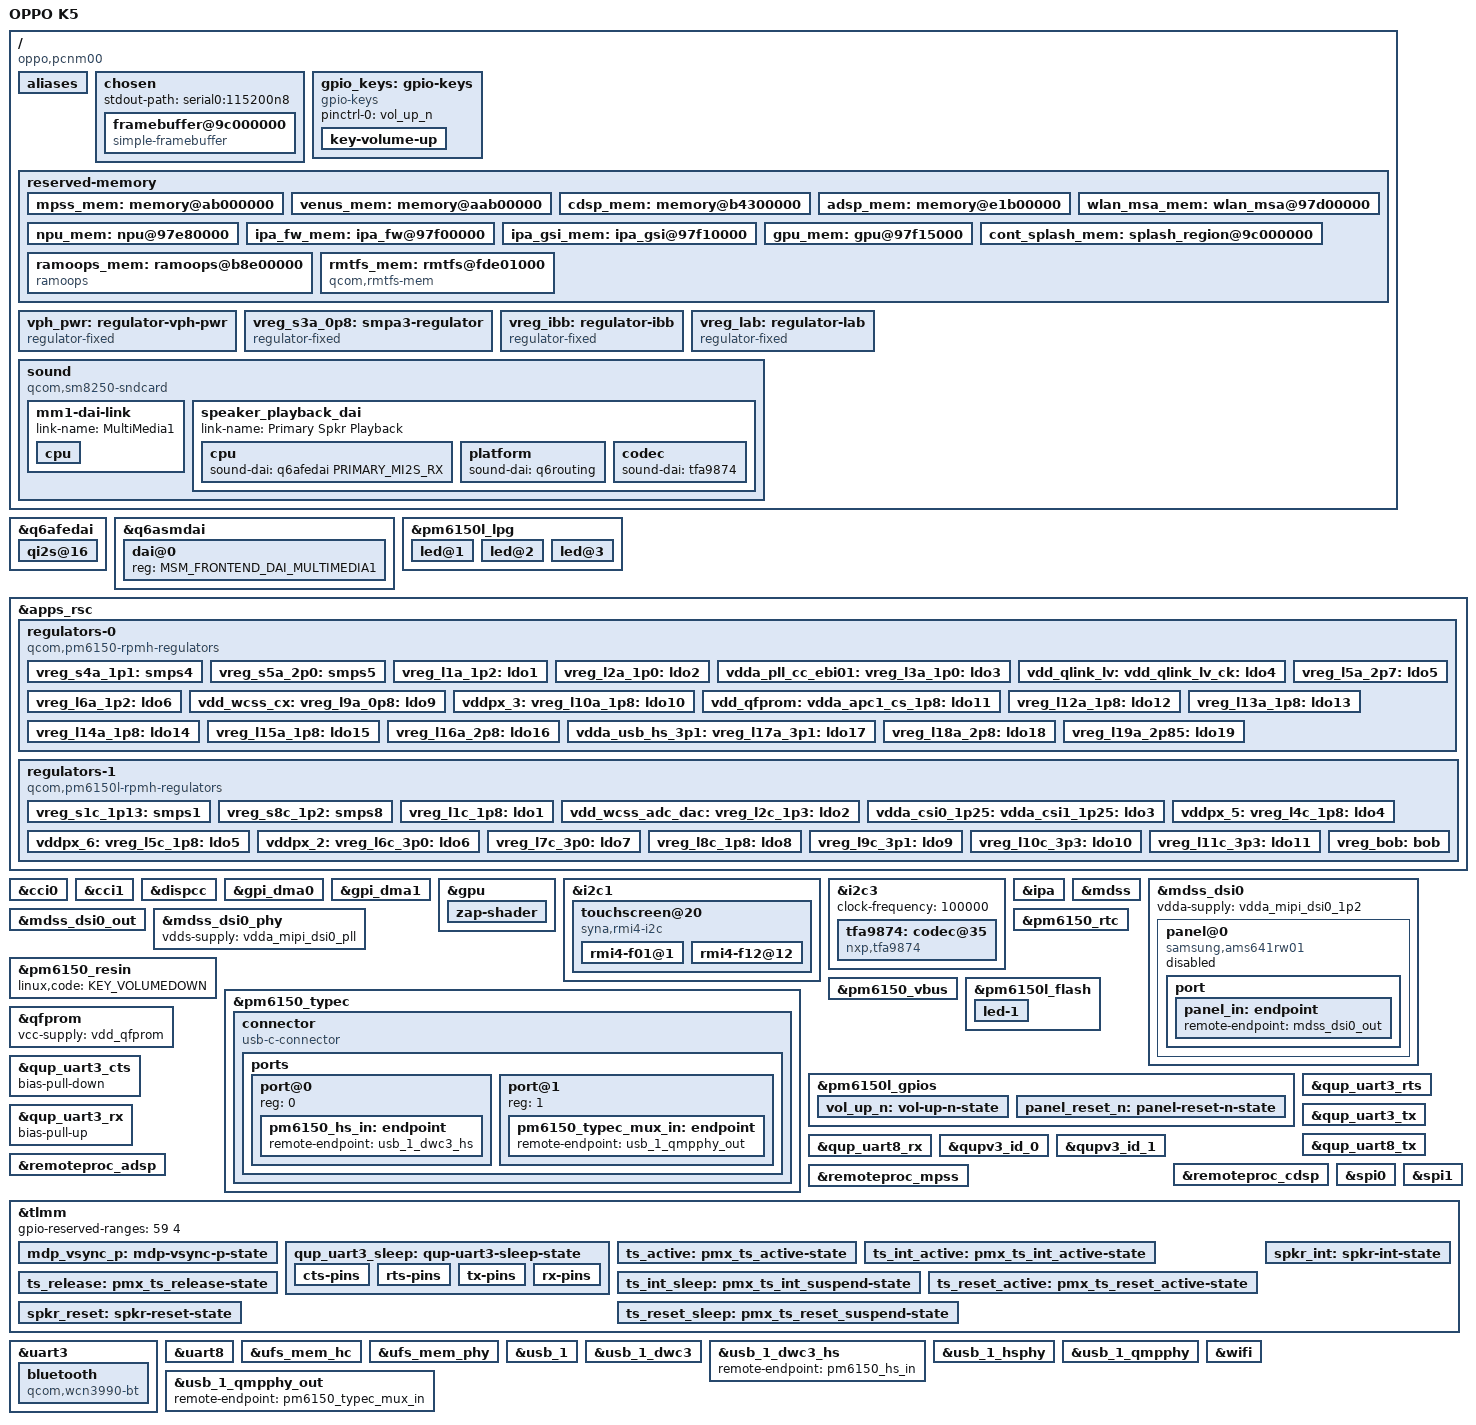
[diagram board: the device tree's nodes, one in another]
// SPDX-License-Identifier: BSD-3-Clause
/*
 * Copyright (c) 2026, XiKoTaSu <3329989998@qq.com>
 */

/dts-v1/;

#include <dt-bindings/firmware/qcom,scm.h>
#include <dt-bindings/gpio/gpio.h>
#include <dt-bindings/leds/common.h>
#include <dt-bindings/pinctrl/qcom,pmic-gpio.h>
#include <dt-bindings/regulator/qcom,rpmh-regulator.h>
#include <dt-bindings/sound/qcom,q6asm.h>
#include <dt-bindings/usb/pd.h>

#include "sm7150.dtsi"
#include "pm6150.dtsi"
#include "pm6150l.dtsi"

/delete-node/ &mpss_mem;
/delete-node/ &venus_mem;
/delete-node/ &cdsp_mem;
/delete-node/ &adsp_mem;
/delete-node/ &wlan_msa_mem;
/delete-node/ &npu_mem;
/delete-node/ &ipa_fw_mem;
/delete-node/ &ipa_gsi_mem;
/delete-node/ &gpu_mem;

/ {
	model = "OPPO K5";
	compatible = "oppo,pcnm00", "qcom,sm7150";
	chassis-type = "handset";

	aliases {
		bluetooth0 = &bluetooth;
		hsuart0 = &uart3;
		serial0 = &uart8;
		wifi0 = &wifi;
	};

	chosen {
		#address-cells = <2>;
		#size-cells = <2>;
		ranges;

		stdout-path = "serial0:115200n8";

		framebuffer@9c000000 {
			compatible = "simple-framebuffer";
			reg = <0x0 0x9c000000 0x0 0x1700000>;
			width = <1080>;
			height = <2340>;
			stride = <(1080 * 4)>;
			format = "a8r8g8b8";

			clocks = <&gcc GCC_DISP_HF_AXI_CLK>;
		};
	};

	gpio_keys: gpio-keys {
		compatible = "gpio-keys";

		pinctrl-0 = <&vol_up_n>;
		pinctrl-names = "default";

		key-volume-up {
			label = "Volume Up";
			gpios = <&pm6150l_gpios 2 GPIO_ACTIVE_LOW>;
			linux,code = <KEY_VOLUMEUP>;
			debounce-interval = <15>;
			linux,can-disable;
			wakeup-source;
		};
	};

    reserved-memory {
		mpss_mem: memory@ab000000 {
			reg = <0x0 0xab000000 0x0 0x8e00000>;
			no-map;
		};

		venus_mem: memory@aab00000 {
			reg = <0x0 0xaab00000 0x0 0x500000>;
			no-map;
		};

		cdsp_mem: memory@b4300000 {
			reg = <0x0 0xb4300000 0x0 0x1e00000>;
			no-map;
		};

		adsp_mem: memory@e1b00000 {
			reg = <0x00 0xe1b00000 0x00 0x2000000>;
			no-map;
		};

		wlan_msa_mem: wlan_msa@97d00000 {
			reg = <0x0 0x97d00000 0x0 0x180000>;
			no-map;
		};

		npu_mem: npu@97e80000 {
			reg = <0x0 0x97e80000 0x0 0x80000>;
			no-map;
		};

		ipa_fw_mem: ipa_fw@97f00000 {
			reg = <0x0 0x97f00000 0x0 0x10000>;
			no-map;
		};

		ipa_gsi_mem: ipa_gsi@97f10000 {
			reg = <0x0 0x97f10000 0x0 0x5000>;
			no-map;
		};

		gpu_mem: gpu@97f15000 {
			reg = <0x0 0x97f15000 0x0 0x2000>;
			no-map;
		};

		cont_splash_mem: splash_region@9c000000 {
			reg = <0x0 0x9c000000 0x0 0x1700000>;
			no-map;
		};

		ramoops_mem: ramoops@b8e00000 {
			compatible = "ramoops";
			reg = <0x0 0xb8e00000 0x0 0x400000>;
			record-size = <0x40000>;
			console-size = <0x40000>;
			ftrace-size = <0x40000>;
			pmsg-size = <0x200000>;
		};

		rmtfs_mem: rmtfs@fde01000 {
			compatible = "qcom,rmtfs-mem";
			reg = <0x0 0xfde01000 0x0 0x200000>;
			no-map;

			qcom,client-id = <1>;
			qcom,vmid = <QCOM_SCM_VMID_MSS_MSA>;
		};
	};

	vph_pwr: regulator-vph-pwr {
		compatible = "regulator-fixed";

		regulator-name = "vph_pwr";
		regulator-min-microvolt = <3700000>;
		regulator-max-microvolt = <3700000>;

		regulator-always-on;
		regulator-boot-on;
	};
	
	// S3A is really mx.lvl but it's there for supply map completeness sake.
	vreg_s3a_0p8: smpa3-regulator {
		compatible = "regulator-fixed";
		regulator-name = "vreg_s3a_0p8";

		regulator-min-microvolt = <800000>;
		regulator-max-microvolt = <800000>;
		regulator-always-on;
		vin-supply = <&vph_pwr>;
	};

	vreg_ibb: regulator-ibb {
		compatible = "regulator-fixed";

		regulator-name = "ibb";
		regulator-min-microvolt = <6000000>;
		regulator-max-microvolt = <6000000>;
	};

	vreg_lab: regulator-lab {
		compatible = "regulator-fixed";

		regulator-name = "lab";
		regulator-min-microvolt = <6100000>;
		regulator-max-microvolt = <6100000>;
	};

	sound {
		compatible = "qcom,sm8250-sndcard";
		pinctrl-0 = <&pri_mi2s_active &pri_mi2s_ws_active>;
		pinctrl-names = "default";
		model = "OPPO K5";

		mm1-dai-link {
			link-name = "MultiMedia1";
			cpu {
				sound-dai = <&q6asmdai MSM_FRONTEND_DAI_MULTIMEDIA1>;
			};
		};

		speaker_playback_dai {
			link-name = "Primary Spkr Playback";
			cpu {
				sound-dai = <&q6afedai PRIMARY_MI2S_RX>;
			};

			platform {
				sound-dai = <&q6routing>;
			};

			codec {
				sound-dai = <&tfa9874>;
			};
		};
	};
};

&q6afedai {
	qi2s@16 {
		reg = <PRIMARY_MI2S_RX>;
		qcom,sd-lines = <0>;
	};
};

&q6asmdai {
	dai@0 {
		reg = <MSM_FRONTEND_DAI_MULTIMEDIA1>;
	};
};

&pm6150l_lpg {
	status = "okay";

	led@1 {
		reg = <1>;
		color = <LED_COLOR_ID_RED>;
		function = LED_FUNCTION_STATUS;
		function-enumerator = <0>;
	};

	led@2 {
		reg = <2>;
		color = <LED_COLOR_ID_RED>;
		function = LED_FUNCTION_STATUS;
		function-enumerator = <1>;
	};

	led@3 {
		reg = <3>;
		color = <LED_COLOR_ID_RED>;
		function = LED_FUNCTION_STATUS;
		function-enumerator = <2>;
	};
};

&apps_rsc {
	regulators-0 {
		compatible = "qcom,pm6150-rpmh-regulators";
		qcom,pmic-id = "a";

		vdd-s1-supply = <&vph_pwr>;
		vdd-s2-supply = <&vph_pwr>;
		vdd-s3-supply = <&vph_pwr>;
		vdd-s4-supply = <&vph_pwr>;
		vdd-s5-supply = <&vph_pwr>;

		vdd-l1-supply = <&vreg_s8c_1p2>;
		vdd-l2-l3-supply = <&vreg_s4a_1p1>;
		vdd-l4-l7-l8-supply = <&vreg_s4a_1p1>;
		vdd-l5-l16-l17-l18-l19-supply = <&vreg_bob>;
		vdd-l6-supply = <&vreg_s8c_1p2>;
		vdd-l9-supply = <&vreg_s3a_0p8>;
		vdd-l10-l14-l15-supply = <&vreg_s5a_2p0>;
		vdd-l11-l12-l13-supply = <&vreg_s5a_2p0>;

		/*
		 * S1, S4, S5 are unused.
		 * S2-S3 and L7-L8 are ARCs:
		 * S2 - gfx.lvl,
		 * S3 - mx.lvl,
		 * L7 - lmx.lvl,
		 * L8 - lcx.lvl.
		 */

		vreg_s4a_1p1: smps4 {
			regulator-name = "vreg_s4a_1p1";
			regulator-min-microvolt = <824000>;
			regulator-max-microvolt = <1120000>;
			regulator-initial-mode = <RPMH_REGULATOR_MODE_HPM>;
		};

		vreg_s5a_2p0: smps5 {
			regulator-name = "vreg_s5a_2p0";
			regulator-min-microvolt = <1744000>;
			regulator-max-microvolt = <2040000>;
			regulator-initial-mode = <RPMH_REGULATOR_MODE_HPM>;
		};

		vreg_l1a_1p2: ldo1 {
			regulator-name = "vreg_l1a_1p2";
			regulator-min-microvolt = <1096000>;
			regulator-max-microvolt = <1304000>;
			regulator-initial-mode = <RPMH_REGULATOR_MODE_HPM>;
		};

		vreg_l2a_1p0: ldo2 {
			regulator-name = "vreg_l2a_1p0";
			regulator-min-microvolt = <944000>;
			regulator-max-microvolt = <1056000>;
			regulator-initial-mode = <RPMH_REGULATOR_MODE_HPM>;
		};

		vdda_pll_cc_ebi01:
		vreg_l3a_1p0: ldo3 {
			regulator-name = "vreg_l3a_1p0";
			regulator-min-microvolt = <968000>;
			regulator-max-microvolt = <1064000>;
			regulator-initial-mode = <RPMH_REGULATOR_MODE_HPM>;
		};

		vdd_qlink_lv:
		vdd_qlink_lv_ck:
		vdd_usb_hs_core:
		vdda_mipi_csi0_0p9:
		vdda_mipi_csi1_0p9:
		vdda_mipi_csi2_0p9:
		vdda_mipi_csi3_0p9:
		vdda_mipi_dsi0_pll:
		vdda_qrefs_0p9:
		vdda_ufs_core:
		vdda_usb_ss_dp_core:
		vreg_l4a_0p88: ldo4 {
			regulator-name = "vreg_l4a_0p88";
			regulator-min-microvolt = <824000>;
			regulator-max-microvolt = <920000>;
			regulator-initial-mode = <RPMH_REGULATOR_MODE_HPM>;
			regulator-allow-set-load;
			regulator-allowed-modes = <RPMH_REGULATOR_MODE_LPM
						   RPMH_REGULATOR_MODE_HPM>;
		};

		vreg_l5a_2p7: ldo5 {
			regulator-name = "vreg_l5a_2p7";
			regulator-min-microvolt = <2600000>;
			regulator-max-microvolt = <2800000>;
			regulator-initial-mode = <RPMH_REGULATOR_MODE_HPM>;
		};

		vreg_l6a_1p2: ldo6 {
			regulator-name = "vreg_l6a_1p2";
			regulator-min-microvolt = <1000000>;
			regulator-max-microvolt = <1304000>;
			regulator-initial-mode = <RPMH_REGULATOR_MODE_HPM>;
		};

		vdd_wcss_cx:
		vreg_l9a_0p8: ldo9 {
			regulator-name = "vreg_l9a_0p8";
			regulator-min-microvolt = <624000>;
			regulator-max-microvolt = <760000>;
			regulator-initial-mode = <RPMH_REGULATOR_MODE_HPM>;
		};

		vddpx_3:
		vreg_l10a_1p8: ldo10 {
			regulator-name = "vreg_l10a_1p8";
			regulator-min-microvolt = <1720000>;
			regulator-max-microvolt = <1832000>;
			regulator-initial-mode = <RPMH_REGULATOR_MODE_HPM>;
		};

		vdd_qfprom:
		vdda_apc1_cs_1p8:
		vdda_qrefs_1p8:
		vdda_usb_hs_1p8:
		vddpx_11:
		vreg_l11a_1p8: ldo11 {
			regulator-name = "vreg_l11a_1p8";
			regulator-min-microvolt = <1696000>;
			regulator-max-microvolt = <1984000>;
			regulator-initial-mode = <RPMH_REGULATOR_MODE_HPM>;
		};

		vreg_l12a_1p8: ldo12 {
			regulator-name = "vreg_l12a_1p8";
			regulator-min-microvolt = <1696000>;
			regulator-max-microvolt = <1952000>;
			regulator-initial-mode = <RPMH_REGULATOR_MODE_HPM>;
			regulator-allow-set-load;
			regulator-allowed-modes = <RPMH_REGULATOR_MODE_LPM
						   RPMH_REGULATOR_MODE_HPM>;
		};

		vreg_l13a_1p8: ldo13 {
			regulator-name = "vreg_l13a_1p8";
			regulator-min-microvolt = <1696000>;
			regulator-max-microvolt = <1904000>;
			regulator-initial-mode = <RPMH_REGULATOR_MODE_HPM>;
		};

		vreg_l14a_1p8: ldo14 {
			regulator-name = "vreg_l14a_1p8";
			regulator-min-microvolt = <1720000>;
			regulator-max-microvolt = <1856000>;
			regulator-initial-mode = <RPMH_REGULATOR_MODE_HPM>;
		};

		vreg_l15a_1p8: ldo15 {
			regulator-name = "vreg_l15a_1p8";
			regulator-min-microvolt = <1696000>;
			regulator-max-microvolt = <1904000>;
			regulator-initial-mode = <RPMH_REGULATOR_MODE_HPM>;
		};

		vreg_l16a_2p8: ldo16 {
			regulator-name = "vreg_l16a_2p8";
			regulator-min-microvolt = <2424000>;
			regulator-max-microvolt = <2976000>;
			regulator-initial-mode = <RPMH_REGULATOR_MODE_HPM>;
		};

		vdda_usb_hs_3p1:
		vreg_l17a_3p1: ldo17 {
			regulator-name = "vreg_l17a_3p1";
			regulator-min-microvolt = <3000000>;
			regulator-max-microvolt = <3232000>;
			regulator-initial-mode = <RPMH_REGULATOR_MODE_HPM>;
		};
		
		vreg_l18a_2p8: ldo18 {
			regulator-min-microvolt = <3000000>;
			regulator-max-microvolt = <3000000>;
			regulator-initial-mode = <RPMH_REGULATOR_MODE_HPM>;
		};

		vreg_l19a_2p85: ldo19 {
			regulator-name = "vreg_l19a_2p85";
			regulator-min-microvolt = <2952000>;
			regulator-max-microvolt = <3304000>;
			regulator-initial-mode = <RPMH_REGULATOR_MODE_HPM>;
			regulator-allow-set-load;
			regulator-allowed-modes = <RPMH_REGULATOR_MODE_LPM
						   RPMH_REGULATOR_MODE_HPM>;
		};
	};

	regulators-1 {
		compatible = "qcom,pm6150l-rpmh-regulators";
		qcom,pmic-id = "c";

		vdd-s1-supply = <&vph_pwr>;
		vdd-s2-supply = <&vph_pwr>;
		vdd-s3-supply = <&vph_pwr>;
		vdd-s4-supply = <&vph_pwr>;
		vdd-s5-supply = <&vph_pwr>;
		vdd-s6-supply = <&vph_pwr>;
		vdd-s7-supply = <&vph_pwr>;
		vdd-s8-supply = <&vph_pwr>;

		vdd-l2-l3-supply = <&vreg_s8c_1p2>;
		vdd-l4-l5-l6-supply = <&vreg_bob>;
		vdd-l7-l11-supply = <&vreg_bob>;
		vdd-l9-l10-supply = <&vreg_bob>;

		vdd-bob-supply = <&vph_pwr>;
		vdd-flash-supply = <&vreg_bob>;
		vdd-rgb-supply = <&vreg_bob>;

		/*
		 * S4, S5 are unused.
		 * S2, S3, S7 are ARCs:
		 * S2-S3 - cx.lvl,
		 * S7 - mss.lvl.
		 */

		vreg_s1c_1p13: smps1 {
			regulator-name = "vreg_s1c_1p13";
			regulator-min-microvolt = <1000000>;
			regulator-max-microvolt = <1200000>;
			regulator-initial-mode = <RPMH_REGULATOR_MODE_HPM>;
		};

		vreg_s8c_1p2: smps8 {
			regulator-name = "vreg_s8c_1p2";
			regulator-min-microvolt = <1200000>;
			regulator-max-microvolt = <1730000>;
			regulator-initial-mode = <RPMH_REGULATOR_MODE_HPM>;
		};

		vreg_l1c_1p8: ldo1 {
			regulator-name = "vreg_l1c_1p8";
			regulator-min-microvolt = <1616000>;
			regulator-max-microvolt = <1984000>;
			regulator-initial-mode = <RPMH_REGULATOR_MODE_HPM>;
		};

		vdd_wcss_adc_dac:
		vreg_l2c_1p3: ldo2 {
			regulator-name = "vreg_l2c_1p3";
			regulator-min-microvolt = <1200000>;
			regulator-max-microvolt = <1352000>;
			regulator-initial-mode = <RPMH_REGULATOR_MODE_HPM>;
		};

		vdda_csi0_1p25:
		vdda_csi1_1p25:
		vdda_csi2_1p25:
		vdda_csi3_1p25:
		vdda_hv_ebi0:
		vdda_mipi_dsi0_1p2:
		vdda_ufs_1p2:
		vdda_usb_ss_dp_1p2:
		vddpx_10:
		vreg_l3c_1p23: ldo3 {
			regulator-name = "vreg_l3c_1p23";
			regulator-min-microvolt = <1144000>;
			regulator-max-microvolt = <1256000>;
			regulator-initial-mode = <RPMH_REGULATOR_MODE_HPM>;
			regulator-allow-set-load;
			regulator-allowed-modes = <RPMH_REGULATOR_MODE_LPM
						   RPMH_REGULATOR_MODE_HPM>;
		};

		vddpx_5:
		vreg_l4c_1p8: ldo4 {
			regulator-name = "vreg_l4c_1p8";
			regulator-min-microvolt = <1648000>;
			regulator-max-microvolt = <2950000>;
			regulator-initial-mode = <RPMH_REGULATOR_MODE_HPM>;
		};

		vddpx_6:
		vreg_l5c_1p8: ldo5 {
			regulator-name = "vreg_l5c_1p8";
			regulator-min-microvolt = <1648000>;
			regulator-max-microvolt = <2950000>;
			regulator-initial-mode = <RPMH_REGULATOR_MODE_HPM>;
		};

		vddpx_2:
		vreg_l6c_3p0: ldo6 {
			regulator-name = "vreg_l6c_3p0";
			regulator-min-microvolt = <1648000>;
			regulator-max-microvolt = <3100000>;
			regulator-initial-mode = <RPMH_REGULATOR_MODE_HPM>;
		};

		vreg_l7c_3p0: ldo7 {
			regulator-name = "vreg_l7c_3p0";
			regulator-min-microvolt = <3000000>;
			regulator-max-microvolt = <3312000>;
			regulator-initial-mode = <RPMH_REGULATOR_MODE_HPM>;
		};

		vreg_l8c_1p8: ldo8 {
			regulator-name = "vreg_l8c_1p8";
			regulator-min-microvolt = <1800000>;
			regulator-max-microvolt = <1904000>;
			regulator-initial-mode = <RPMH_REGULATOR_MODE_HPM>;
		};

		vreg_l9c_3p1: ldo9 {
			regulator-name = "vreg_l9c_3p1";
			regulator-min-microvolt = <2950000>;
			regulator-max-microvolt = <3312000>;
			regulator-initial-mode = <RPMH_REGULATOR_MODE_HPM>;
		};

		vreg_l10c_3p3: ldo10 {
			regulator-name = "vreg_l10c_3p3";
			regulator-min-microvolt = <3200000>;
			regulator-max-microvolt = <3312000>;
			regulator-initial-mode = <RPMH_REGULATOR_MODE_HPM>;
		};

		vreg_l11c_3p3: ldo11 {
			regulator-name = "vreg_l11c_3p3";
			regulator-min-microvolt = <2950000>;
			regulator-max-microvolt = <3400000>;
			regulator-initial-mode = <RPMH_REGULATOR_MODE_HPM>;
		};

		vreg_bob: bob {
			regulator-name = "vreg_bob";
			regulator-min-microvolt = <3296000>;
			regulator-max-microvolt = <3960000>;
			regulator-initial-mode = <RPMH_REGULATOR_MODE_AUTO>;
			regulator-allow-bypass;
		};
	};
};

&cci0 {
	status = "okay";
};

&cci1 {
	status = "okay";
};

&dispcc {
	status = "okay";
};

&gpi_dma0 {
	status = "okay";
};

&gpi_dma1 {
	status = "okay";
};

&gpu {
	zap-shader {
		firmware-name = "qcom/sm7150/oppo/pcnm00/a615_zap.mbn";
	};
};

&i2c1 {
	status = "okay";
	#address-cells = <1>;
    #size-cells = <0>;

	touchscreen@20 {
		compatible = "syna,rmi4-i2c";
		reg = <0x20>;
		
		/* Interrupt Configuration */
		interrupt-parent = <&tlmm>;
		interrupts = <9 IRQ_TYPE_LEVEL_LOW>;
		
		/* Reset GPIO */
		reset-gpios = <&tlmm 8 GPIO_ACTIVE_LOW>;
		
		/* Power Configuration */
		vdd-supply = <&vreg_l7c_3p0>;
		vio-supply = <&vreg_l12a_1p8>;
		
		touchscreen-size-x = <1080>;
		touchscreen-size-y = <2340>;
		
		/* Pin Control */
		pinctrl-names = "default";
		pinctrl-0 = <&ts_int_active &ts_reset_active>;
		
		/* Startup Delay */
		syna,startup-delay-ms = <100>;
		
		/* RMI4 Function Descriptors */
		#address-cells = <1>;
		#size-cells = <0>;
		
		/* Function 01: RMI Device Control */
		rmi4-f01@1 {
			reg = <0x1>;
			syna,nosleep-mode = <2>; /* 2 = enable nosleep (disabling sleep) */
		};
		
		/* Function 12: 2D Touch Reporting */
		rmi4-f12@12 {
			reg = <0x12>;
			syna,sensor-type = <1>; /* 1 = touchscreen */
			
			/* Clip coordinates */
			syna,clip-x-high = <1079>; /* 1080-1 */
			syna,clip-y-high = <2339>; /* 2340-1 */
			
			/* Touchscreen properties */
		/*	touchscreen-size-x = <1080>;
			touchscreen-size-y = <2340>;*/
		};
	};
};

&i2c3 {
	clock-frequency = <100000>;
	status = "okay";

	tfa9874: codec@35 {
		compatible = "nxp,tfa9874";
		reg = <0x34>;

		reset-gpio = <&tlmm 12 GPIO_ACTIVE_HIGH>;
		irq-gpio = <&tlmm 56 GPIO_ACTIVE_HIGH>;

		pinctrl-names = "default";
		pinctrl-0 = <&spkr_reset &spkr_int>;

		#sound-dai-cells = <0>;
	};
};

&ipa {
	memory-region = <&ipa_fw_mem>;
	firmware-name = "qcom/sm7150/oppo/pcnm00/ipa_fws.mbn";
	status = "okay";
};

&mdss {
	status = "okay";
};

&mdss_dsi0 {
	vdda-supply = <&vdda_mipi_dsi0_1p2>;

	panel@0 {
		compatible = "samsung,ams641rw01";
	        status = "disabled";
		reg = <0>;

		reset-gpios = <&pm6150l_gpios 9 GPIO_ACTIVE_LOW>;

		vddio-supply = <&vreg_l13a_1p8>;
		vdd3p3-supply = <&vreg_l7c_3p0>;
		vsn-supply = <&vreg_ibb>;
		vsp-supply = <&vreg_lab>;
		
		pinctrl-0 = <&panel_reset_n &mdp_vsync_p>;
		pinctrl-names = "default";

		port {
			panel_in: endpoint {
				remote-endpoint = <&mdss_dsi0_out>;
			};
		};
	};
};

&mdss_dsi0_out {
	data-lanes = <0 1 2 3>;
	remote-endpoint = <&panel_in>;
	status = "okay";
};

&mdss_dsi0_phy {
	vdds-supply = <&vdda_mipi_dsi0_pll>;
	status = "okay";
};

&pm6150_resin {
	linux,code = <KEY_VOLUMEDOWN>;
	status = "okay";
};

&pm6150_rtc {
	status = "okay";
};

&pm6150_typec {
	vdd-vbus-supply = <&pm6150_vbus>;
	vdd-pdphy-supply = <&vdda_usb_hs_3p1>;
	status = "okay";

	connector {
		compatible = "usb-c-connector";

		power-role = "source";
		data-role = "dual";
		self-powered;

		source-pdos = <PDO_FIXED(5000, 3000, PDO_FIXED_DUAL_ROLE |
			       PDO_FIXED_USB_COMM | PDO_FIXED_DATA_SWAP)>;

		ports {
			#address-cells = <1>;
			#size-cells = <0>;

			port@0 {
				reg = <0>;
				pm6150_hs_in: endpoint {
					remote-endpoint = <&usb_1_dwc3_hs>;
				};
			};


			port@1 {
				reg = <1>;
				pm6150_typec_mux_in: endpoint {
					remote-endpoint = <&usb_1_qmpphy_out>;
				};
			};
		};
	};
};

&pm6150_vbus {
	regulator-min-microamp = <500000>;
	regulator-max-microamp = <3000000>;
	status = "okay";
};

&pm6150l_flash {
	status = "okay";

	led-1 {
		function = LED_FUNCTION_FLASH;
		color = <LED_COLOR_ID_WHITE>;
		led-sources = <1>;
		led-max-microamp = <150000>;
		flash-max-microamp = <1000000>;
		flash-max-timeout-us = <1280000>;
	};
};

&pm6150l_gpios {
	vol_up_n: vol-up-n-state {
		pins = "gpio2";
		function = PMIC_GPIO_FUNC_NORMAL;
		input-enable;
		bias-pull-up;
		power-source = <0>;
	};

	panel_reset_n: panel-reset-n-state {
		pins = "gpio9";
		function = PMIC_GPIO_FUNC_FUNC1;
		qcom,drive-strength = <PMIC_GPIO_STRENGTH_MED>;
		bias-disable;
		output-low;
		power-source = <1>;
	};
};

&qfprom {
	vcc-supply = <&vdd_qfprom>;
};

&qup_uart3_cts {
	bias-pull-down;
};

&qup_uart3_rts {
	drive-strength = <2>;
	bias-disable;
};

&qup_uart3_tx {
	drive-strength = <2>;
	bias-disable;
};

&qup_uart3_rx {
	bias-pull-up;
};

&qup_uart8_tx {
	drive-strength = <2>;
	bias-disable;
};

&qup_uart8_rx {
	drive-strength = <2>;
	bias-pull-up;
};

&qupv3_id_0 {
	status = "okay";
};

&qupv3_id_1 {
	status = "okay";
};

&remoteproc_adsp {
	firmware-name = "qcom/sm7150/oppo/pcnm00/adsp.mbn";
	status = "okay";
};

&remoteproc_cdsp {
	firmware-name = "qcom/sm7150/oppo/pcnm00/cdsp.mbn";
	status = "okay";
};

&remoteproc_mpss {
	firmware-name = "qcom/sm7150/oppo/pcnm00/modem.mbn";
	status = "okay";
};

&spi0 {
	status = "okay";
};

&spi1 {
	status = "okay";
};

&tlmm {
	gpio-reserved-ranges = <59 4>;
	
	mdp_vsync_p: mdp-vsync-p-state {
		pins = "gpio10";
		function = "mdp_vsync";
		drive-strength = <2>;
		bias-pull-down;
	};

	qup_uart3_sleep: qup-uart3-sleep-state {
		cts-pins {
			pins = "gpio38";
			function = "gpio";
			bias-pull-down;
		};

		rts-pins {
			pins = "gpio39";
			function = "gpio";
			bias-pull-down;
		};

		tx-pins {
			pins = "gpio40";
			function = "gpio";
			bias-pull-up;
		};

		rx-pins {
			pins = "gpio41";
			function = "gpio";
			bias-pull-up;
		};
	};
	
	ts_active: pmx_ts_active-state {
		pins = "gpio8", "gpio9";
		function = "gpio";
		drive-strength = <0x08>;
		bias-pull-up;
	};

	ts_int_active: pmx_ts_int_active-state {
		pins = "gpio9";
		function = "gpio";
		drive-strength = <0x08>;
		bias-pull-up;
	};

	ts_int_sleep: pmx_ts_int_suspend-state {
		pins = "gpio9";
		function = "gpio";
		drive-strength = <0x02>;
		bias-pull-down;
	};

	ts_reset_active: pmx_ts_reset_active-state{
		pins = "gpio8";
		function = "gpio";
		drive-strength = <0x08>;
		input-disable;
		bias-disable;
	};

	ts_reset_sleep: pmx_ts_reset_suspend-state {
		pins = "gpio8";
		function = "gpio";
		drive-strength = <0x02>;					
		input-disable;
		bias-pull-down;
	};

	ts_release: pmx_ts_release-state {
		pins = "gpio9", "gpio8";
		function = "gpio";
		drive-strength = <0x02>;
		bias-pull-down;
	};
	
	spkr_reset: spkr-reset-state {
		pins = "gpio12";
		function = "gpio";
		drive-strength = <2>;
		bias-disable;
		bias-pull-down;
		output-low;
	};

	spkr_int: spkr-int-state {
		pins = "gpio56";
		function = "gpio";
		drive-strength = <2>;
		bias-pull-up;
		input-enable;
	};
};

&uart3 {
	/delete-property/interrupts;
	interrupts-extended = <&intc GIC_SPI 604 IRQ_TYPE_LEVEL_HIGH>,
			      <&tlmm 41 IRQ_TYPE_EDGE_FALLING>;

	pinctrl-1 = <&qup_uart3_sleep>;
	pinctrl-names = "default",
			"sleep";

	status = "okay";

	bluetooth: bluetooth {
		compatible = "qcom,wcn3990-bt";

		vddio-supply = <&vreg_l10a_1p8>;
		vddxo-supply = <&vreg_l1c_1p8>;
		vddrf-supply = <&vdd_wcss_adc_dac>;
		vddch0-supply = <&vreg_l10c_3p3>;
		max-speed = <3200000>;
	};
};

&uart8 {
	status = "okay";
};

&ufs_mem_hc {
	reset-gpios = <&tlmm 119 GPIO_ACTIVE_LOW>;

	vcc-supply = <&vreg_l19a_2p85>;
	vcc-max-microamp = <600000>;
	vccq2-supply = <&vreg_l12a_1p8>;
	vccq2-max-microamp = <600000>;
	status = "okay";
};

&ufs_mem_phy {
	vdda-phy-supply = <&vdda_ufs_core>;
	vdda-pll-supply = <&vdda_ufs_1p2>;
	status = "okay";
};

&usb_1 {
	status = "okay";
};

&usb_1_dwc3 {
	dr_mode = "otg";
	usb-role-switch;
};

&usb_1_dwc3_hs {
	remote-endpoint = <&pm6150_hs_in>;
};

&usb_1_hsphy {
	vdd-supply = <&vdd_usb_hs_core>;
	vdda-pll-supply = <&vdda_usb_hs_1p8>;
	vdda-phy-dpdm-supply = <&vdda_usb_hs_3p1>;
	status = "okay";
};

&usb_1_qmpphy {
	vdda-pll-supply = <&vdda_usb_ss_dp_1p2>;
	vdda-phy-supply = <&vdda_usb_ss_dp_core>;
	orientation-switch;
	status = "okay";
};

&usb_1_qmpphy_out {
	remote-endpoint = <&pm6150_typec_mux_in>;
};

&wifi {
	vdd-0.8-cx-mx-supply = <&vdd_wcss_cx>;
	vdd-1.8-xo-supply = <&vreg_l1c_1p8>;
	vdd-1.3-rfa-supply = <&vdd_wcss_adc_dac>;
	vdd-3.3-ch0-supply = <&vreg_l10c_3p3>;
	vdd-3.3-ch1-supply = <&vreg_l11c_3p3>;

	qcom,ath10k-calibration-variant = "oppo_pcnm00";

	status = "okay";
};
